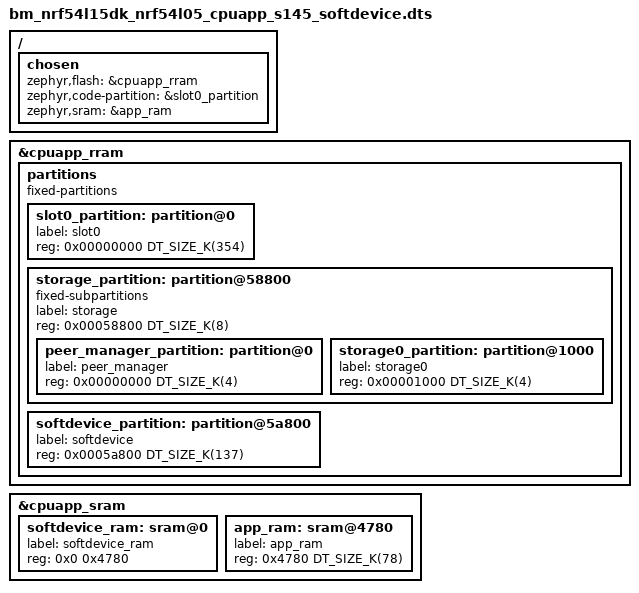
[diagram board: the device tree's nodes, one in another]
/*
 * Copyright (c) 2025 Nordic Semiconductor ASA
 *
 * SPDX-License-Identifier: LicenseRef-Nordic-5-Clause
 */

/dts-v1/;

#include <nordic/nrf54l05_cpuapp.dtsi>
#include "bm_nrf54l15dk_nrf54l05_cpuapp_common.dtsi"

/ {
	chosen {
		zephyr,flash = &cpuapp_rram;
		zephyr,code-partition = &slot0_partition;
		zephyr,sram = &app_ram;
	};
};

&cpuapp_rram {
	status = "okay";

	partitions {
		compatible = "fixed-partitions";
		#address-cells = <1>;
		#size-cells = <1>;

		slot0_partition: partition@0 {
			label = "slot0";
			reg = <0x00000000 DT_SIZE_K(354)>;
		};

		storage_partition: partition@58800 {
			compatible = "fixed-subpartitions";
			label = "storage";
			reg = <0x00058800 DT_SIZE_K(8)>;
			ranges = <0x0 0x58800 DT_SIZE_K(8)>;
			#address-cells = <1>;
			#size-cells = <1>;

			peer_manager_partition: partition@0 {
				label = "peer_manager";
				reg = <0x00000000 DT_SIZE_K(4)>;
			};

			storage0_partition: partition@1000 {
				label = "storage0";
				reg = <0x00001000 DT_SIZE_K(4)>;
			};
		};

		softdevice_partition: partition@5a800 {
			label = "softdevice";
			reg = <0x0005a800 DT_SIZE_K(137)>;
		};
	};
};

&cpuapp_sram {
	status = "okay";

	softdevice_ram: sram@0 {
		label = "softdevice_ram";
		reg = <0x0 0x4780>;
	};

	app_ram: sram@4780 {
		label = "app_ram";
		reg = <0x4780 DT_SIZE_K(78)>;
	};
};
